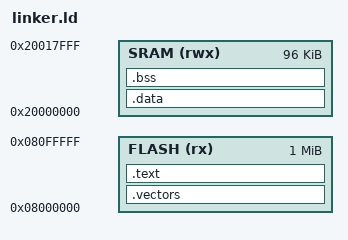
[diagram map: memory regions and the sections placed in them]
/* Minimal linker script for STM32L476RG */

ENTRY(Reset_Handler)

MEMORY
{
    FLASH (rx) : ORIGIN = 0x08000000, LENGTH = 1024K
    SRAM  (rwx): ORIGIN = 0x20000000, LENGTH = 96K
}

SECTIONS
{
    .vectors :
    {
        KEEP(*(.vectors))
    } > FLASH

    .text :
    {
        *(.text*)
        *(.rodata*)
        . = ALIGN(4);
        _etext = .;
    } > FLASH

    .data : AT( _etext )
    {
        _sdata = .;
        *(.data*)
        . = ALIGN(4);
        _edata = .;
    } > SRAM

    .bss :
    {
        _sbss = .;
        *(.bss*)
        *(COMMON)
        . = ALIGN(4);
        _ebss = .;
    } > SRAM

    _end = .;
}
